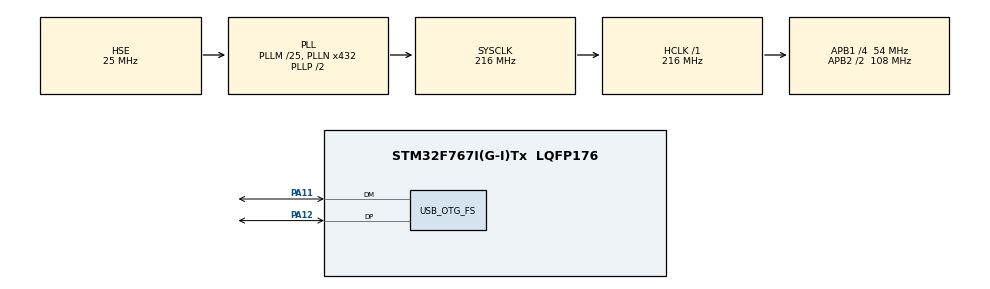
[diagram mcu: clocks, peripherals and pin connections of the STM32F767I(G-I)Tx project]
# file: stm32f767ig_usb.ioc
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Mcu.Family=STM32F7
RCC.CortexFreq_Value=216000000
PA11.Mode=Device_Only
RCC.APB1CLKDivider=RCC_HCLK_DIV4
RCC.SYSCLKSource=RCC_SYSCLKSOURCE_PLLCLK
ProjectManager.StackSize=0x400
PA13.Signal=SYS_JTMS-SWDIO
PA12.Signal=USB_OTG_FS_DP
ProjectManager.TargetToolchain=Makefile
PH0/OSC_IN.Mode=HSE-External-Oscillator
RCC.HCLKFreq_Value=216000000
RCC.APB2TimFreq_Value=216000000
PH1/OSC_OUT.Signal=RCC_OSC_OUT
RCC.USBFreq_Value=48000000
RCC.LSE_VALUE=32768
RCC.AHBFreq_Value=216000000
RCC.HSE_VALUE=25000000
board=custom
RCC.VCOOutputFreq_Value=432000000
PH0/OSC_IN.Signal=RCC_OSC_IN
RCC.APB2Freq_Value=108000000
PA14.Mode=Serial_Wire
PA13.Mode=Serial_Wire
PH1/OSC_OUT.Mode=HSE-External-Oscillator
Mcu.Name=STM32F767I(G-I)Tx
RCC.SYSCLKFreq_VALUE=216000000
Mcu.Package=LQFP176
PA12.Mode=Device_Only
NVIC.OTG_FS_IRQn=true\:0\:0\:false\:false\:true\:true\:true
PA11.Signal=USB_OTG_FS_DM
PA14.Signal=SYS_JTCK-SWCLK
USB_OTG_FS.VirtualMode=Device_Only
ProjectManager.HeapSize=0x200
RCC.HSI_VALUE=16000000
RCC.PLLQ=9
NVIC.PriorityGroup=NVIC_PRIORITYGROUP_4
RCC.APB2CLKDivider=RCC_HCLK_DIV2
RCC.PLLM=25
RCC.PLLN=432
RCC.APB1TimFreq_Value=108000000
RCC.APB1Freq_Value=54000000

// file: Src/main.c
/* USER CODE BEGIN Header */
/**
 ******************************************************************************
 * @file           : main.c
 * @brief          : Main program body
 ******************************************************************************
 * @attention
 *
 * <h2><center>&copy; Copyright (c) 2021 STMicroelectronics.
 * All rights reserved.</center></h2>
 *
 * This software component is licensed by ST under Ultimate Liberty license
 * SLA0044, the "License"; You may not use this file except in compliance with
 * the License. You may obtain a copy of the License at:
 *                             www.st.com/SLA0044
 *
 ******************************************************************************
 */
/* USER CODE END Header */
#include "main.h"
#include "gpio.h"

/* USER CODE BEGIN Includes */
#include "usbd_cdc_if.h"
/* USER CODE END Includes */

void SystemClock_Config(void);

int main(void)
{

    /* MCU Configuration--------------------------------------------------------*/

    /* Reset of all peripherals, Initializes the Flash interface and the Systick. */
    HAL_Init();

    /* Configure the system clock */
    SystemClock_Config();

    /* Initialize all configured peripherals */
    MX_GPIO_Init();
    /* USER CODE BEGIN 2 */
    extern void USB_DEVICE_Init(void);
    USB_DEVICE_Init();

    /* USER CODE END 2 */

    /* Infinite loop */
    /* USER CODE BEGIN WHILE */
    const char *str = "hello,world\r\n";
    while (1)
    {
        CDC_Transmit_FS((uint8_t *)str, strlen(str));
        HAL_Delay(1000);
        /* USER CODE END WHILE */

    }
}

void SystemClock_Config(void)
{
    RCC_OscInitTypeDef RCC_OscInitStruct = {0};
    RCC_ClkInitTypeDef RCC_ClkInitStruct = {0};
    RCC_PeriphCLKInitTypeDef PeriphClkInitStruct = {0};

    /** Configure the main internal regulator output voltage
     */
    __HAL_RCC_PWR_CLK_ENABLE();
    __HAL_PWR_VOLTAGESCALING_CONFIG(PWR_REGULATOR_VOLTAGE_SCALE1);
    /** Initializes the RCC Oscillators according to the specified parameters
     * in the RCC_OscInitTypeDef structure.
     */
    RCC_OscInitStruct.OscillatorType = RCC_OSCILLATORTYPE_HSE;
    RCC_OscInitStruct.HSEState = RCC_HSE_ON;
    RCC_OscInitStruct.PLL.PLLState = RCC_PLL_ON;
    RCC_OscInitStruct.PLL.PLLSource = RCC_PLLSOURCE_HSE;
    RCC_OscInitStruct.PLL.PLLM = 25;
    RCC_OscInitStruct.PLL.PLLN = 432;
    RCC_OscInitStruct.PLL.PLLP = RCC_PLLP_DIV2;
    RCC_OscInitStruct.PLL.PLLQ = 9;
    if (HAL_RCC_OscConfig(&RCC_OscInitStruct) != HAL_OK)
    {
        Error_Handler();
    }
    /** Activate the Over-Drive mode
     */
    if (HAL_PWREx_EnableOverDrive() != HAL_OK)
    {
        Error_Handler();
    }
    /** Initializes the CPU, AHB and APB buses clocks
     */
    RCC_ClkInitStruct.ClockType = RCC_CLOCKTYPE_HCLK | RCC_CLOCKTYPE_SYSCLK | RCC_CLOCKTYPE_PCLK1 | RCC_CLOCKTYPE_PCLK2;
    RCC_ClkInitStruct.SYSCLKSource = RCC_SYSCLKSOURCE_PLLCLK;
    RCC_ClkInitStruct.AHBCLKDivider = RCC_SYSCLK_DIV1;
    RCC_ClkInitStruct.APB1CLKDivider = RCC_HCLK_DIV4;
    RCC_ClkInitStruct.APB2CLKDivider = RCC_HCLK_DIV2;

    if (HAL_RCC_ClockConfig(&RCC_ClkInitStruct, FLASH_LATENCY_7) != HAL_OK)
    {
        Error_Handler();
    }
    PeriphClkInitStruct.PeriphClockSelection = RCC_PERIPHCLK_CLK48;
    PeriphClkInitStruct.Clk48ClockSelection = RCC_CLK48SOURCE_PLL;
    if (HAL_RCCEx_PeriphCLKConfig(&PeriphClkInitStruct) != HAL_OK)
    {
        Error_Handler();
    }
}

void Error_Handler(void)
{
    __disable_irq();
    while (1)
    {
    }
}

/************************ (C) COPYRIGHT STMicroelectronics *****END OF FILE****/
